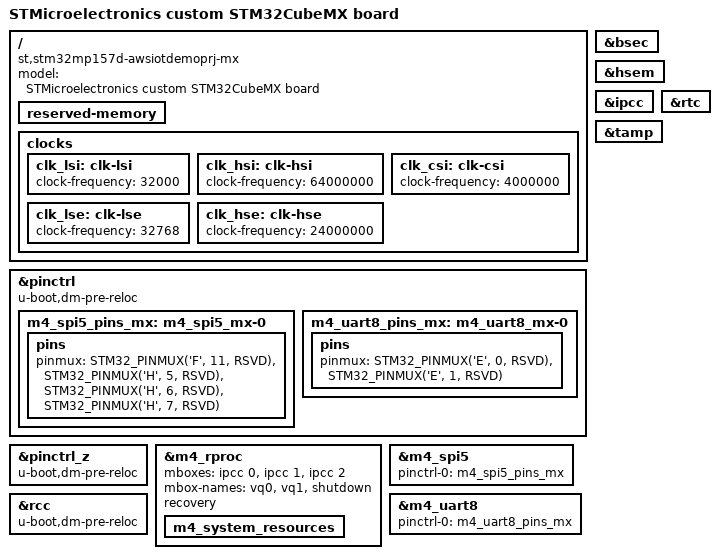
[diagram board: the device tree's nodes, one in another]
/* SPDX-License-Identifier: (GPL-2.0+ OR BSD-3-Clause) */
/*
 * Copyright (C) STMicroelectronics 2025 - All Rights Reserved
 * Author: STM32CubeMX code generation for STMicroelectronics.
 */

/* For more information on Device Tree configuration, please refer to
 * https://wiki.st.com/stm32mpu/wiki/Category:Device_tree_configuration
 */

/dts-v1/;
#include "stm32mp157c.dtsi"
#include "stm32mp157cac-pinctrl.dtsi"
#include "stm32mp157c-m4-srm.dtsi"

/* USER CODE BEGIN includes */
/* USER CODE END includes */

/ {
	model = "STMicroelectronics custom STM32CubeMX board";
	compatible = "st,stm32mp157d-awsiotdemoprj-mx", "st,stm32mp157";

	/* !!! log : Warning - no DDR config found: 'memory' node not generated  !!! */

	/*
	memory@??? {
		reg = < ??? >;
	};
	*/

	reserved-memory {
		#address-cells = <1>;
		#size-cells = <1>;
		ranges;

		/* USER CODE BEGIN reserved-memory */
		/* USER CODE END reserved-memory */

		/* !!! log : Warning - no DDR config found: 'gpu_reserved' node not generated  !!! */

		/*
		gpu_reserved: gpu@??? {
			reg = <??? ???}>;
			no-map;
		};
		*/
	};

	/* USER CODE BEGIN root */
	/* USER CODE END root */

	clocks {
		/* USER CODE BEGIN clocks */
		/* USER CODE END clocks */

		clk_lsi: clk-lsi {
			clock-frequency = <32000>;
		};

		clk_hsi: clk-hsi {
			clock-frequency = <64000000>;
		};

		clk_csi: clk-csi {
			clock-frequency = <4000000>;
		};

		clk_lse: clk-lse {
			clock-frequency = <32768>;
		};

		clk_hse: clk-hse {
			clock-frequency = <24000000>;
		};
	};

}; /*root*/

&pinctrl {
	u-boot,dm-pre-reloc;

	m4_spi5_pins_mx: m4_spi5_mx-0 {
		pins {
			pinmux = <STM32_PINMUX('F', 11, RSVD)>, /* SPI5_MOSI */
					 <STM32_PINMUX('H', 5, RSVD)>, /* SPI5_NSS */
					 <STM32_PINMUX('H', 6, RSVD)>, /* SPI5_SCK */
					 <STM32_PINMUX('H', 7, RSVD)>; /* SPI5_MISO */
		};
	};

	m4_uart8_pins_mx: m4_uart8_mx-0 {
		pins {
			pinmux = <STM32_PINMUX('E', 0, RSVD)>, /* UART8_RX */
					 <STM32_PINMUX('E', 1, RSVD)>; /* UART8_TX */
		};
	};

	/* USER CODE BEGIN pinctrl */
	/* USER CODE END pinctrl */
};

&pinctrl_z {
	u-boot,dm-pre-reloc;

	/* USER CODE BEGIN pinctrl_z */
	/* USER CODE END pinctrl_z */
};

&m4_rproc{
	/*Restriction: "memory-region" property is not managed - please to use User-Section if needed*/
	mboxes = <&ipcc 0>, <&ipcc 1>, <&ipcc 2>;
	mbox-names = "vq0", "vq1", "shutdown";
	recovery;
	status = "okay";

	/* USER CODE BEGIN m4_rproc */
	/* USER CODE END m4_rproc */

	m4_system_resources{
		status = "okay";

		/* USER CODE BEGIN m4_system_resources */
		/* USER CODE END m4_system_resources */
	};
};

&bsec{
	status = "okay";

	/* USER CODE BEGIN bsec */
	/* USER CODE END bsec */
};

&hsem{
	status = "okay";

	/* USER CODE BEGIN hsem */
	/* USER CODE END hsem */
};

&ipcc{
	status = "okay";

	/* USER CODE BEGIN ipcc */
	/* USER CODE END ipcc */
};

&m4_spi5{
	pinctrl-names = "default";
	pinctrl-0 = <&m4_spi5_pins_mx>;
	status = "okay";

	/* USER CODE BEGIN m4_spi5 */
	/* USER CODE END m4_spi5 */
};

&m4_uart8{
	pinctrl-names = "default";
	pinctrl-0 = <&m4_uart8_pins_mx>;
	status = "okay";

	/* USER CODE BEGIN m4_uart8 */
	/* USER CODE END m4_uart8 */
};

&rcc{
	u-boot,dm-pre-reloc;
	status = "okay";

	/* USER CODE BEGIN rcc */
	/* USER CODE END rcc */
};

&rtc{
	status = "okay";

	/* USER CODE BEGIN rtc */
	/* USER CODE END rtc */
};

&tamp{
	status = "okay";

	/* USER CODE BEGIN tamp */
	/* USER CODE END tamp */
};

/* USER CODE BEGIN addons */
/* USER CODE END addons */

